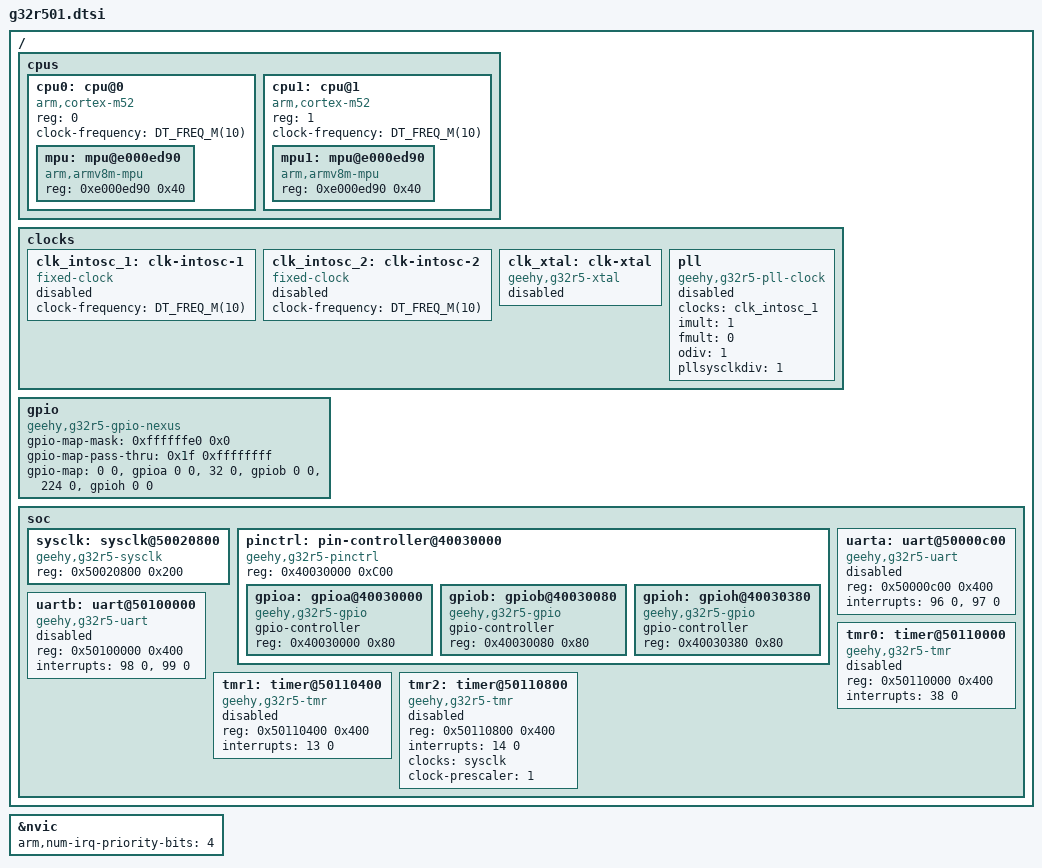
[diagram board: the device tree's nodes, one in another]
/*
 * Copyright (c) 2025 Quincy.W <wangqyfm@foxmail.com>
 *
 * SPDX-License-Identifier: Apache-2.0
 *
 * Shared G32R501 peripherals. Both cores are declared here.
 * Include one of the following instead of this file from a board:
 *   g32r501_cpu0.dtsi    dual-core CPU0 (ITCM 48 KiB, DTCM 16 KiB)
 *   g32r501_cpu1.dtsi    dual-core CPU1 (ITCM 8 KiB, DTCM 8 KiB)
 *   g32r501_single.dtsi  single-core    (ITCM 64 KiB, DTCM 16 KiB)
 *
 * IPC is a coprocessor channel (see sdk ipc.h), not an MMIO block,
 * so it has no node here. Only dual-core images can use it.
 */

#include <arm/armv8.1-m.dtsi>
#include <zephyr/dt-bindings/i2c/i2c.h>
#include <zephyr/dt-bindings/gpio/gpio.h>
#include <zephyr/dt-bindings/adc/adc.h>
#include <freq.h>
#include <mem.h>

/ {
	cpus {
		#address-cells = <1>;
		#size-cells = <0>;

		cpu0: cpu@0 {
			compatible = "arm,cortex-m52";
			reg = <0>;
			#address-cells = <1>;
			#size-cells = <1>;
			clock-frequency = <DT_FREQ_M(10)>;

			mpu: mpu@e000ed90 {
				compatible = "arm,armv8m-mpu";
				reg = <0xe000ed90 0x40>;
			};
		};

		cpu1: cpu@1 {
			compatible = "arm,cortex-m52";
			reg = <1>;
			#address-cells = <1>;
			#size-cells = <1>;
			clock-frequency = <DT_FREQ_M(10)>;

			mpu1: mpu@e000ed90 {
				compatible = "arm,armv8m-mpu";
				reg = <0xe000ed90 0x40>;
			};
		};
	};

	clocks {
		clk_intosc_1: clk-intosc-1 {
			#clock-cells = <0>;
			compatible = "fixed-clock";
			clock-frequency = <DT_FREQ_M(10)>;
			status = "disabled";
		};

		clk_intosc_2: clk-intosc-2 {
			#clock-cells = <0>;
			compatible = "fixed-clock";
			clock-frequency = <DT_FREQ_M(10)>;
			status = "disabled";
		};

		clk_xtal: clk-xtal {
			#clock-cells = <0>;
			compatible = "geehy,g32r5-xtal";
			status = "disabled";
		};

		pll: pll {
			#clock-cells = <0>;
			compatible = "geehy,g32r5-pll-clock";
			clocks = <&clk_intosc_1>;
			imult = <1>;
			fmult = <0>;
			odiv = <1>;
			pllsysclkdiv = <1>;
			status = "disabled";
		};
	};

	gpio: gpio {
		compatible = "geehy,g32r5-gpio-nexus";
		#gpio-cells = <2>;
		gpio-map-mask = <0xffffffe0 0x0>;
		gpio-map-pass-thru = <0x1f 0xffffffff>;
		gpio-map = <0 0 &gpioa 0 0>,
			   <32 0 &gpiob 0 0>,
			   <224 0 &gpioh 0 0>;
	};

	soc {
		sysclk: sysclk@50020800 {
			compatible = "geehy,g32r5-sysclk";
			#clock-cells = <0>;
			reg = <0x50020800 0x200>;
		};

		pinctrl: pin-controller@40030000 {
			compatible = "geehy,g32r5-pinctrl";
			#address-cells = <1>;
			#size-cells = <1>;
			reg = <0x40030000 0xC00>;

			gpioa: gpioa@40030000 {
				compatible = "geehy,g32r5-gpio";
				gpio-controller;
				#gpio-cells = <2>;
				reg = <0x40030000 0x80>;
			};

			gpiob: gpiob@40030080 {
				compatible = "geehy,g32r5-gpio";
				gpio-controller;
				#gpio-cells = <2>;
				reg = <0x40030080 0x80>;
			};

			gpioh: gpioh@40030380 {
				compatible = "geehy,g32r5-gpio";
				gpio-controller;
				#gpio-cells = <2>;
				reg = <0x40030380 0x80>;
			};
		};

		uarta: uart@50000c00 {
			compatible = "geehy,g32r5-uart";
			reg = <0x50000c00 0x400>;
			interrupts = <96 0>, <97 0>;
			interrupt-names = "rx", "tx";
			status = "disabled";
		};
		uartb: uart@50100000 {
			compatible = "geehy,g32r5-uart";
			reg = <0x50100000 0x400>;
			interrupts = <98 0>, <99 0>;
			interrupt-names = "rx", "tx";
			status = "disabled";
		};

		/*
		 * CPU timers. Each core image has its own TMR0/1/2 at these
		 * addresses. TMR0 and TMR1 run from SYSCLK. TMR2 selects its
		 * clock with clocks and divides it with clock-prescaler.
		 */
		tmr0: timer@50110000 {
			compatible = "geehy,g32r5-tmr";
			reg = <0x50110000 0x400>;
			interrupts = <38 0>;
			status = "disabled";
		};

		tmr1: timer@50110400 {
			compatible = "geehy,g32r5-tmr";
			reg = <0x50110400 0x400>;
			interrupts = <13 0>;
			status = "disabled";
		};

		tmr2: timer@50110800 {
			compatible = "geehy,g32r5-tmr";
			reg = <0x50110800 0x400>;
			interrupts = <14 0>;
			clocks = <&sysclk>;
			clock-prescaler = <1>;
			status = "disabled";
		};
	};
};

&nvic {
	arm,num-irq-priority-bits = <4>;
};
